# STM32G0B0xx register map
File version: 1.0
Registers are 32-bit, read-write, reset 0x0 unless marked. A register's access mark holds for its fields unless they carry their own. Offsets are from the block's base; [hi:lo] are bit positions; {n}, {i} and the like mark numbered series.

## SYSCFG — System configuration controller
Base 0x40010000
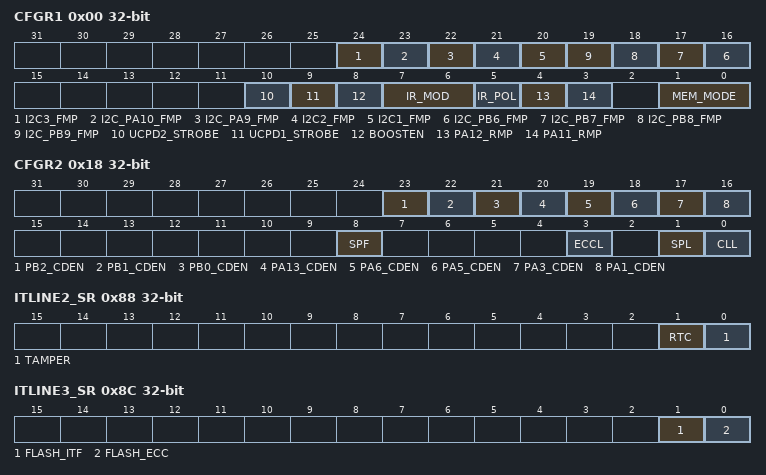
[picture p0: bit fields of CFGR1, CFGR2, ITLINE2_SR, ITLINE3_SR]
0x00 CFGR1 — SYSCFG configuration register 1
  [24] I2C3_FMP — Enable I2C3 Fast mode plus
  [23] I2C_PA10_FMP — Enable Fast Mode Plus on PA10
  [22] I2C_PA9_FMP — Enable Fast Mode Plus on PA9
  [21] I2C2_FMP — Enable I2C2 Fast mode plus
  [20] I2C1_FMP — Enable Fast Mode Plus on PB10, PB11, PF6 and PF7
  [n+10] I2C_PB{n}_FMP (n=6..9) — I2C PB{n} Fast mode plus
  [10] UCPD2_STROBE — Strobe signal bit for UCPD2
  [9] UCPD1_STROBE — Strobe signal bit for UCPD1
  [8] BOOSTEN — I/O analog switch voltage booster enable
  [7:6] IR_MOD — IRDA Modulation Envelope signal source selection
    0=TIM16 (00: Timer16 is selected as IRDA Modulation envelope source); 1=USART1 (01: USART1 is selected as IRDA Modulation envelope source); 2=USART4 (10: USART4 is selected as IRDA Modulation envelope source)
  [5] IR_POL — IROut Polarity Selection
    1=INVERTED (1: Output of IRDA (IROut) inverted); 0=NOT_INVERTED (0: Output of IRDA (IROut) not inverted)
  [4] PA12_RMP — PA12 Remap
  [3] PA11_RMP — PA11 Remap
  [1:0] MEM_MODE — SYSCFG_Memory Remap Config
    0=FLASH (Main Flash memory mapped at 0x00000000); 1=SYSTEMFLASH (System Flash memory mapped at 0x00000000); 3=SRAM (Embedded SRAM mapped at 0x00000000)
0x18 CFGR2 — SYSCFG configuration register 2
  [23] PB2_CDEN — PB[2] Clamping Diode Enable
  [22] PB1_CDEN — PB[1] Clamping Diode Enable
  [21] PB0_CDEN — PB[0] Clamping Diode Enable
  [20] PA13_CDEN — PA[13] Clamping Diode Enable
  [19] PA6_CDEN — PA[6] Clamping Diode Enable
  [18] PA5_CDEN — PA[5] Clamping Diode Enable
  [17] PA3_CDEN — PA[3] Clamping Diode Enable
  [16] PA1_CDEN — PA[1] Clamping Diode Enable
  [8] SPF — SRAM Parity error flag
  [3] ECCL
  [1] SPL — Enables and locks the SRAM_PARITY error signal with Break Input of TIMER1
  [0] CLL — Enables and locks the LOCKUP (Hardfault) output of CortexM0 with Break Input of TIMER1
0x80 ITLINE0_SR — SYSCFG configuration IT_LINE register
  [0] EWDG — EWDG interrupt
0x84 IT_LINE_SR1 — SYSCFG configuration IT_LINE register
0x88 ITLINE2_SR — SYSCFG configuration IT_LINE register
  [1] RTC — RTC -> exti[19] interrupt
  [0] TAMPER — TAMPER -> exti[21] interrupt
0x8C ITLINE3_SR — SYSCFG configuration IT_LINE register
  [1] FLASH_ITF — FLASH ITF interrupt
  [0] FLASH_ECC — Flash ITF ECC interrupt
0x90 ITLINE4_SR — SYSCFG configuration IT_LINE register
  [0] CLK_CTRL — RCC interrupt
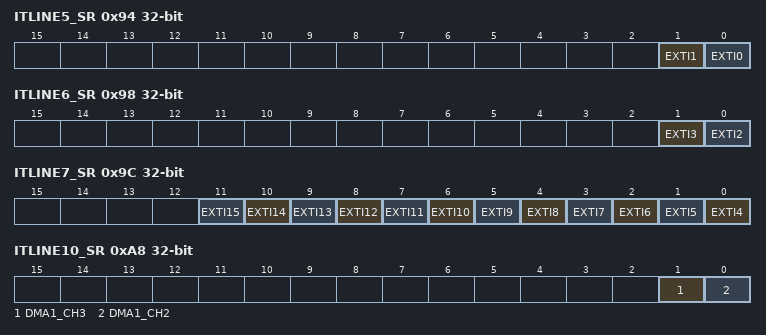
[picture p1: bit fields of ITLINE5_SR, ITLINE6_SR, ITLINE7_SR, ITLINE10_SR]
0x94 ITLINE5_SR — SYSCFG configuration IT_LINE register
  [1] EXTI1 — External Interrupt 1
  [0] EXTI0 — External Interrupt 0
0x98 ITLINE6_SR — SYSCFG configuration IT_LINE register
  [1] EXTI3 — External Interrupt 3
  [0] EXTI2 — External Interrupt 2
0x9C ITLINE7_SR — SYSCFG configuration IT_LINE register
  [n-4] EXTI{n} (n=4..15) — External Interrupt {n}
0xA0 ITLINE8_SR — SYSCFG configuration IT_LINE register
  [2] USB — USB Interrupt
0xA4 ITLINE9_SR — SYSCFG configuration IT_LINE register
  [0] DMA1_CH1 — DMA1 Channel 1 Interrupt
0xA8 ITLINE10_SR — SYSCFG configuration IT_LINE register
  [1] DMA1_CH3 — DMA2 Channel 3 Interrupt
  [0] DMA1_CH2 — DMA1 Channel 2 Interrupt
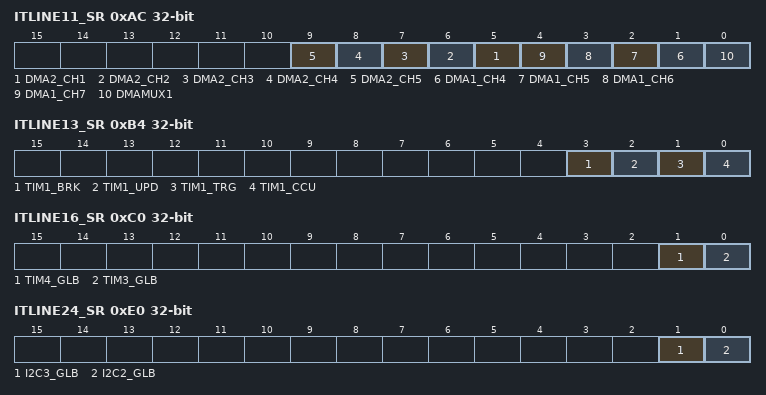
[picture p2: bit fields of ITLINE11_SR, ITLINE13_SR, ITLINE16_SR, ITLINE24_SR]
0xAC ITLINE11_SR — SYSCFG configuration IT_LINE register
  [n+4] DMA2_CH{n} (n=1..5) — DMA2 Channel {n} Interrupt
  [n-3] DMA1_CH{n} (n=4..7) — DMA1 Channel {n} Interrupt
  [0] DMAMUX1 — DMAMUX Interrupt
0xB0 ITLINE12_SR — SYSCFG configuration IT_LINE register
  [0] ADC — ADC Interrupt
0xB4 ITLINE13_SR — SYSCFG configuration IT_LINE register
  [3] TIM1_BRK — TIM1 BRK Interrupt
  [2] TIM1_UPD — TIM1 UPD Interrupt
  [1] TIM1_TRG — TIM1 TRG Interrupt
  [0] TIM1_CCU — TIM1 CCU Interrupt
0xB8 ITLINE14_SR — SYSCFG configuration IT_LINE register
  [0] TIM1_CC — TIM1 CC Interrupt
0xBC IT_LINE_SR15 — SYSCFG configuration IT_LINE register
0xC0 ITLINE16_SR — SYSCFG configuration IT_LINE register
  [1] TIM4_GLB — TIM4 GLB Interrupt
  [0] TIM3_GLB — TIM3 GLB Interrupt
0xC4 ITLINE17_SR — SYSCFG configuration IT_LINE register
  [0] TIM6_GLB — TIM6 GLB Interrupt
0xC8 ITLINE18_SR — SYSCFG configuration IT_LINE register
  [0] TIM7_GLB — TIM7 GLB Interrupt
{0x80+4i} ITLINE{i}_SR (i=19..22) — SYSCFG configuration IT_LINE register
  [0] TIM{i-5}_GLB — TIM{i-5} GLB Interrupt
0xDC ITLINE23_SR — SYSCFG configuration IT_LINE register
  [0] I2C1_GLB — I2C1 GLB Interrupt -> exti[23]
0xE0 ITLINE24_SR — SYSCFG configuration IT_LINE register
  [1] I2C3_GLB — I2C3 GLB Interrupt -> exti[24]
  [0] I2C2_GLB — I2C2 GLB Interrupt -> exti[22]
0xE4 ITLINE25_SR — SYSCFG configuration IT_LINE register
  [0] SPI1 — SPI1 Interrupt
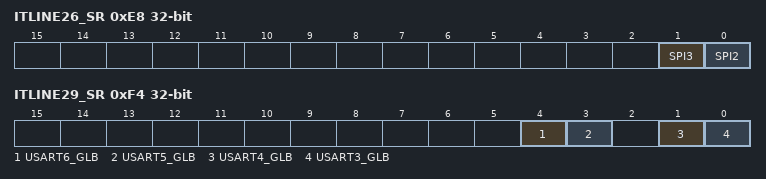
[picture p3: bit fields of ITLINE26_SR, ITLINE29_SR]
0xE8 ITLINE26_SR — SYSCFG configuration IT_LINE register
  [1] SPI3 — SPI3 Interrupt
  [0] SPI2 — SPI2 Interrupt
0xEC ITLINE27_SR — SYSCFG configuration IT_LINE register
  [0] USART1_GLB — USART1 GLB Interrupt -> exti[25]
0xF0 ITLINE28_SR — SYSCFG configuration IT_LINE register
  [0] USART2_GLB — USART2 GLB Interrupt -> exti[26]
0xF4 ITLINE29_SR — SYSCFG configuration IT_LINE register
  [4] USART6_GLB — USART6 GLB Interrupt
  [3] USART5_GLB — USART5 GLB Interrupt
  [1] USART4_GLB — USART4 GLB Interrupt
  [0] USART3_GLB — USART3 GLB Interrupt
0xF8 IT_LINE_SR30 — SYSCFG configuration IT_LINE register
0xFC IT_LINE_SR31 — SYSCFG configuration IT_LINE register
